# LPC43xx register map
File version: 10
CPU: CM4 r0p0, little endian, no MPU, no FPU, 3 interrupt priority bits
Registers are 32-bit, read-write, reset 0x0 unless marked. A register's access mark holds for its fields unless they carry their own. Offsets are from the block's base; [hi:lo] are bit positions; {n}, {i} and the like mark numbered series; 'fields as' and 'values as' point back to an identical list.

## GPDMA — General Purpose DMA (GPDMA)
Base 0x40002000
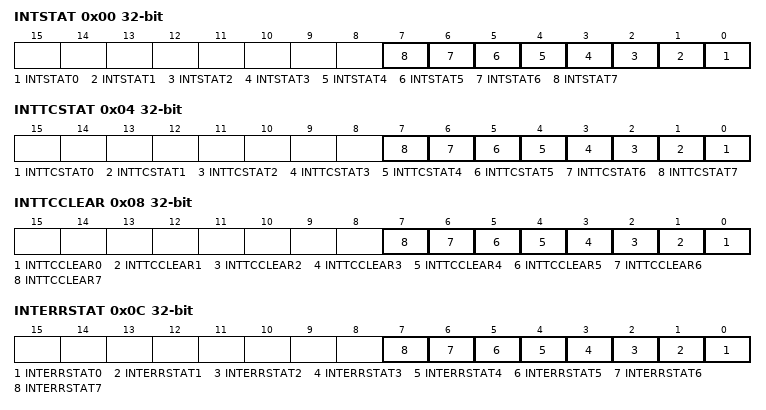
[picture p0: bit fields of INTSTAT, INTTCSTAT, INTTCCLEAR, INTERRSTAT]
0x00 INTSTAT ro — DMA Interrupt Status Register
  [n] INTSTAT{n} (n=0..7) — Status of DMA channel interrupts after masking. Each bit represents one channel: 0 - the corresponding channel has no active interrupt request. 1 - the corresponding channel does have an active interrupt request.
0x04 INTTCSTAT ro — DMA Interrupt Terminal Count Request Status Register
  [n] INTTCSTAT{n} (n=0..7) — Terminal count interrupt request status for DMA channels. Each bit represents one channel: 0 - the corresponding channel has no active terminal count interrupt request. 1 - the corresponding channel does have an active terminal count interrupt request.
0x08 INTTCCLEAR wo reset not defined — DMA Interrupt Terminal Count Request Clear Register
  [n] INTTCCLEAR{n} (n=0..7) — Allows clearing the Terminal count interrupt request (IntTCStat) for DMA channels. Each bit represents one channel: 0 - writing 0 has no effect. 1 - clears the corresponding channel terminal count interrupt.
0x0C INTERRSTAT ro — DMA Interrupt Error Status Register
  [n] INTERRSTAT{n} (n=0..7) — Interrupt error status for DMA channels. Each bit represents one channel: 0 - the corresponding channel has no active error interrupt request. 1 - the corresponding channel does have an active error interrupt request.
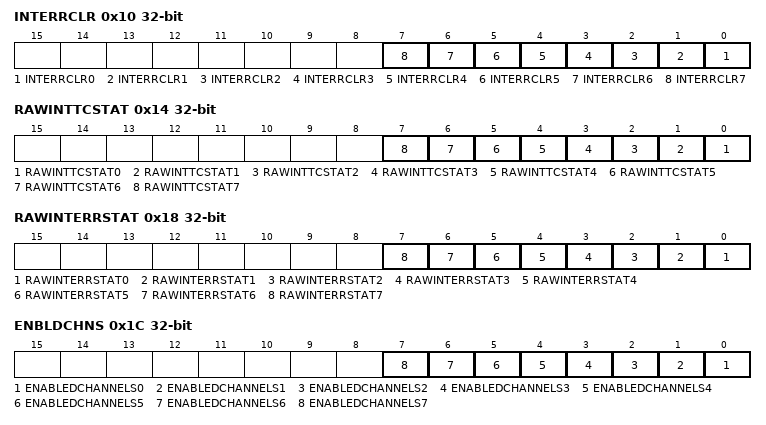
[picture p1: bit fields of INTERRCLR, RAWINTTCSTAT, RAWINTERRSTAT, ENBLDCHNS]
0x10 INTERRCLR wo reset not defined — DMA Interrupt Error Clear Register
  [n] INTERRCLR{n} (n=0..7) — Writing a 1 clears the error interrupt request (IntErrStat) for DMA channels. Each bit represents one channel: 0 - writing 0 has no effect. 1 - clears the corresponding channel error interrupt.
0x14 RAWINTTCSTAT ro — DMA Raw Interrupt Terminal Count Status Register
  [n] RAWINTTCSTAT{n} (n=0..7) — Status of the terminal count interrupt for DMA channels prior to masking. Each bit represents one channel: 0 - the corresponding channel has no active terminal count interrupt request. 1 - the corresponding channel does have an active terminal count interrupt request.
0x18 RAWINTERRSTAT ro — DMA Raw Error Interrupt Status Register
  [n] RAWINTERRSTAT{n} (n=0..7) — Status of the error interrupt for DMA channels prior to masking. Each bit represents one channel: 0 - the corresponding channel has no active error interrupt request. 1 - the corresponding channel does have an active error interrupt request.
0x1C ENBLDCHNS ro — DMA Enabled Channel Register
  [n] ENABLEDCHANNELS{n} (n=0..7) — Enable status for DMA channels. Each bit represents one channel: 0 - DMA channel is disabled. 1 - DMA channel is enabled.
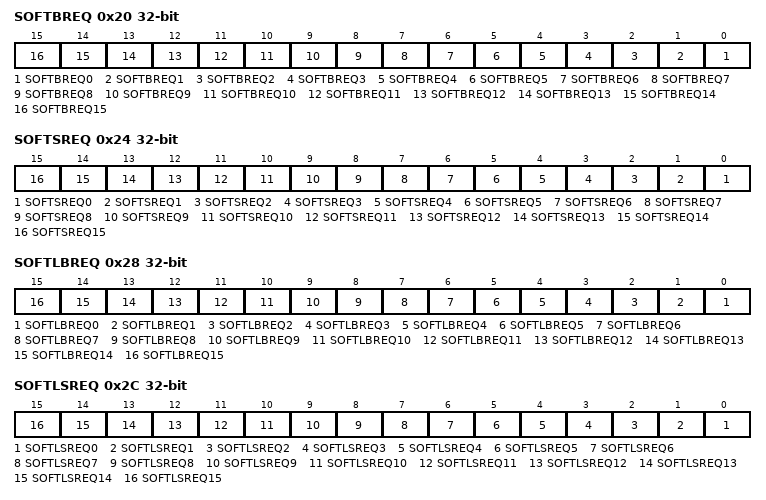
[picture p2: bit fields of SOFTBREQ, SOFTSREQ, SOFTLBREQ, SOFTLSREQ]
0x20 SOFTBREQ — DMA Software Burst Request Register
  [n] SOFTBREQ{n} (n=0..15) — Software burst request flags for each of 16 possible sources. Each bit represents one DMA request line or peripheral function (refer to Table 136 for peripheral hardware connections to the DMA controller): 0 - writing 0 has no effect. 1 - writing 1 generates a DMA burst request for the corresponding request line.
0x24 SOFTSREQ — DMA Software Single Request Register
  [n] SOFTSREQ{n} (n=0..15) — Software single transfer request flags for each of 16 possible sources. Each bit represents one DMA request line or peripheral function: 0 - writing 0 has no effect. 1 - writing 1 generates a DMA single transfer request for the corresponding request line.
0x28 SOFTLBREQ — DMA Software Last Burst Request Register
  [n] SOFTLBREQ{n} (n=0..15) — Software last burst request flags for each of 16 possible sources. Each bit represents one DMA request line or peripheral function: 0 - writing 0 has no effect. 1 - writing 1 generates a DMA last burst request for the corresponding request line.
0x2C SOFTLSREQ — DMA Software Last Single Request Register
  [n] SOFTLSREQ{n} (n=0..15) — Software last single transfer request flags for each of 16 possible sources. Each bit represents one DMA request line or peripheral function: 0 - writing 0 has no effect. 1 - writing 1 generates a DMA last single transfer request for the corresponding request line.
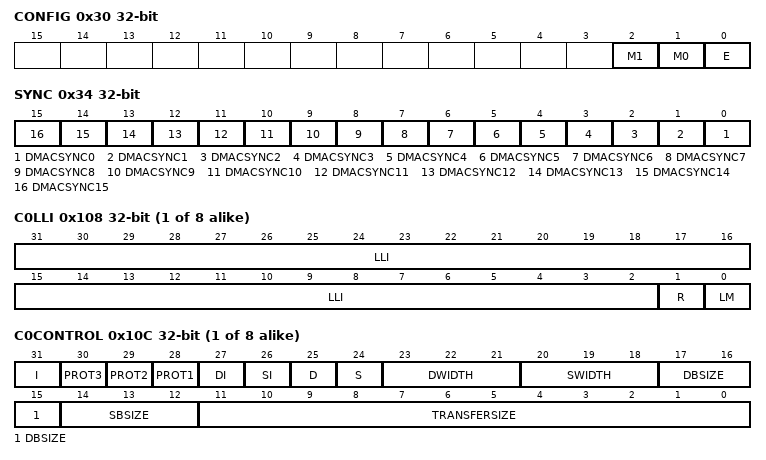
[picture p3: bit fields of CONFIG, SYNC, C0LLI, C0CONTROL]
0x30 CONFIG — DMA Configuration Register
  [2] M1 — AHB Master 1 endianness configuration:
    0=LITTLE_ENDIAN_MODE (Little-endian mode (default).); 1=BIG_ENDIAN_MODE_
  [1] M0 — AHB Master 0 endianness configuration:
    values as M1
  [0] E — DMA Controller enable:
    0=DISABLED__DEFAULT_ (Disabled (default). Disabling the DMA Controller reduces power consumption.); 1=ENABLED
0x34 SYNC — DMA Synchronization Register
  [n] DMACSYNC{n} (n=0..15) — Controls the synchronization logic for DMA request signals. Each bit represents one set of DMA request lines as described in the preceding text: 0 - synchronization logic for the corresponding DMA request signals are enabled. 1 - synchronization logic for the corresponding request line signals are disabled.
{0x100+0x20*i} C{i}SRCADDR (i=0..7) — DMA Channel Source Address Register
  [31:0] SRCADDR — DMA source address. Reading this register will return the current source address.
{0x104+0x20*i} C{i}DESTADDR (i=0..7) — DMA Channel Destination Address Register
  [31:0] DESTADDR — DMA Destination address. Reading this register will return the current destination address.
{0x108+0x20*i} C{i}LLI (i=0..7) — DMA Channel Linked List Item Register
  [31:2] LLI — Linked list item. Bits [31:2] of the address for the next LLI. Address bits [1:0] are 0.
  [1] R — Reserved, and must be written as 0, masked on read.
  [0] LM — AHB master select for loading the next LLI:
    0=AHB_MASTER_0_; 1=AHB_MASTER_1_
{0x10C+0x20*i} C{i}CONTROL (i=0..7) — DMA Channel Control Register
  [31] I — Terminal count interrupt enable bit.
    0=THE_TERMINAL_COUNT_INTERRUPT_IS_DISABLED; 1=THE_TERMINAL_COUNT_INTERRUPT_IS_ENABLED
  [30] PROT3 — Indicates that the access is cacheable or not cacheable:
    0=ACCESS_IS_NOT_CACHEA (Access is not cacheable.); 1=ACCESS_IS_CACHEABLE_
  [29] PROT2 — Indicates that the access is bufferable or not bufferable:
    0=ACCESS_IS_NOT_BUFFER (Access is not bufferable.); 1=ACCESS_IS_BUFFERABLE
  [28] PROT1 — Indicates that the access is in user mode or privileged mode:
    0=ACCESS_IS_IN_USER_MO (Access is in user mode); 1=ACCESS_IS_IN_PRIVILE (Access is in privileged mode.)
  [27] DI — Destination increment:
    0=THE_DESTINATION_ADDRESS_IS_NOT_INCREMENTED (The destination address is not incremented after each transfer.); 1=THE_DESTINATION_ADDRESS_IS_INCREMENTED (The destination address is incremented after each transfer.)
  [26] SI — Source increment:
    0=NOT_INCREMENT (The source address is not incremented after each transfer.); 1=INCREMENT (The source address is incremented after each transfer.)
  [25] D — Destination AHB master select: Only Master1 can access a peripheral. Master0 can only access memory.
    0=AHB_MASTER_0_SELECTE (AHB Master 0 selected for destination transfer.); 1=AHB_MASTER_1_SELECTE (AHB Master 1 selected for destination transfer.)
  [24] S — Source AHB master select:
    0=AHB_MASTER_0_SELECTE (AHB Master 0 selected for source transfer.); 1=AHB_MASTER_1_SELECTE (AHB Master 1 selected for source transfer.)
  [23:21] DWIDTH — Destination transfer width. Transfers wider than the AHB master bus width are not supported. The source and destination widths can be different from each other. The hardware automatically packs and unpacks the data as required. 0x3 to 0x7 - Reserved.
    0=BYTE_8_BIT; 1=HALFWORD_16_BIT; 2=WORD_32_BIT
  [20:18] SWIDTH — Source transfer width. Transfers wider than the AHB master bus width are illegal. The source and destination widths can be different from each other. The hardware automatically packs and unpacks the data as required. 0x3 to 0x7 - Reserved.
    0=BYTE_8_BIT; 1=HALFWORD_16_BIT; 2=WORD_32_BIT
  [17:15] DBSIZE — Destination burst size. Indicates the number of transfers that make up a destination burst transfer request. This value must be set to the burst size of the destination peripheral or, if the destination is memory, to the memory boundary size. The burst size is the amount of data that is transferred when the BREQ signal goes active in the destination peripheral.
    0=DESTINATION_BURST_1 (Destination burst size = 1); 1=DESTINATION_BURST_4 (Destination burst size = 4); 2=DESTINATION_BURST_8 (Destination burst size = 8); 3=DESTINATION_BURST_16 (Destination burst size = 16); 4=DESTINATION_BURST_32 (Destination burst size = 32); 5=DESTINATION_BURST_64 (Destination burst size = 64); 6=DESTINATION_BURST_128 (Destination burst size = 128); 7=DESTINATION_BURST_256 (Destination burst size = 256)
  [14:12] SBSIZE — Source burst size. Indicates the number of transfers that make up a source burst. This value must be set to the burst size of the source peripheral, or if the source is memory, to the memory boundary size (see Figure 3). The burst size is the amount of data that is transferred when the BREQ signal goes active in the source peripheral.
    0=SOURCE_BURST_1 (Source burst size = 1); 1=SOURCE_BURST_4 (Source burst size = 4); 2=SOURCE_BURST_8 (Source burst size = 8); 3=SOURCE_BURST_16 (Source burst size = 16); 4=SOURCE_BURST_32 (Source burst size = 32); 5=SOURCE_BURST_64 (Source burst size = 64); 6=SOURCE_BURST_128 (Source burst size = 128); 7=SOURCE_BURST_256 (Source burst size = 256)
  [11:0] TRANSFERSIZE — Transfer size in byte. A write to this field sets the size of the transfer when the DMA Controller is the flow controller. The transfer size value must be set before the channel is enabled. Transfer size is updated as data transfers are completed. A read from this field indicates the number of transfers completed on the destination bus. Reading the register when the channel is active does not give useful information because by the time that the software has processed the value read, the channel might have progressed. It is intended to be used only when a channel is enabled and then disabled. The transfer size value is not used if the DMA Controller is not the flow controller.
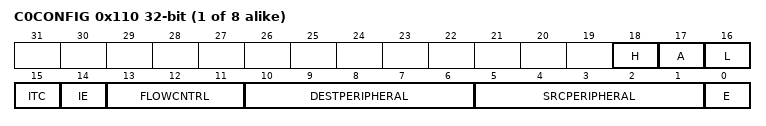
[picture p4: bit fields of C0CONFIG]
{0x110+0x20*i} C{i}CONFIG (i=0..7) — DMA Channel Configuration Register
  [18] H — Halt: 0 = enable DMA requests. 1 = ignore further source DMA requests. The contents of the channel FIFO are drained. This value can be used with the Active and Channel Enable bits to cleanly disable a DMA channel.
    0=ENABLE_DMA_REQUESTS_; 1=IGNORE_FURTHER_SOURC (Ignore further source DMA requests.)
  [17] A — Active: 0 = there is no data in the FIFO of the channel. 1 = the channel FIFO has data. This value can be used with the Halt and Channel Enable bits to cleanly disable a DMA channel. This is a read-only bit.
  [16] L — Lock. When set, this bit enables locked transfers.
  [15] ITC — Terminal count interrupt mask. When cleared, this bit masks out the terminal count interrupt of the relevant channel.
  [14] IE — Interrupt error mask. When cleared, this bit masks out the error interrupt of the relevant channel.
  [13:11] FLOWCNTRL — Flow control and transfer type. This value indicates the flow controller and transfer type. The flow controller can be the DMA Controller, the source peripheral, or the destination peripheral. The transfer type can be memory-to-memory, memory-to-peripheral, peripheral-to-memory, or peripheral-to-peripheral. Refer to Table 157 for the encoding of this field.
    0=MEMORY_TO_MEMORY (Memory to memory (DMA control)); 1=MEMORY_TO_PERIPHERAL_DMA_CONTROL; 2=PERIPHERAL_TO_MEMORY_DMA_CONTROL; 3=SOURCE_PERIPHERAL_TO_DMA_CONTROL (Source peripheral to destination peripheral (DMA control)); 4=SOURCE_PERIPHERAL_TO_DEST_CONTROL (Source peripheral to destination peripheral (destination control)); 5=MEMORY_TO_PERIPHERAL_PERIPHERAL_CONTROL; 6=PERIPHERAL_TO_MEMORY_PERIPHERAL_CONTROL; 7=SOURCE_PERIPHERAL_TO_SOURCE_CONTROL (Source peripheral to destination peripheral (source control))
  [10:6] DESTPERIPHERAL — Destination peripheral. This value selects the DMA destination request peripheral. This field is ignored if the destination of the transfer is to memory. See Table 136 for details.
    0=DESTINATION_EQ_SPIFI (Destination = SPIFI); 1=DESTINATION_EQ_TIMER_0_MATCH_0_UART0_TRANSMIT (Destination = Timer 0 match 0/UART0 transmit); 2=DESTINATION_EQ_TIMER_0_MATCH_1_UART0_RECEIEVE (Destination = Timer 0 match 1/UART0 receive); 3=DESTINATION_EQ_TIMER_1_MATCH_0_UART1_TRANSMIT (Destination = Timer 1 match 0/UART1 transmit); 4=DESTINATION_EQ_TIMER_1_MATCH_1_UART1_RECEIVE (Destination = Timer 1 match 1/UART 1 receive); 5=DESTINATION_EQ_TIMER_2_MATCH_0_UART2_TRANSMIT (Destination = Timer 2 match 0/UART 2 transmit); 6=DESTINATION_EQ_TIMER_2_MATCH_1_UART2_RECEIVE (Destination = Timer 2 match 1/UART 2 receive); 7=DESTINATION_EQ_TIMER_3_MATCH_0_UART3_TRANSMIT_DMA_REQ_0 (Destination = Timer 3 match 0/UART3 transmit/SCT DMA request 0); 8=DESTINATION_EQ_TIMER_3_MATCH_1_UART3_RECEIVE_DMA_REQ_1 (Destination = Timer 3 match 1/UART3 receive/SCT DMA request 1); 9=DESTINATION_EQ_SSP0_RECEIVE_CH0 (Destination = SSP0 receive/I2S channel 0); 10=DESTINATION_EQ_SSP0_TRANSMIT_CH1 (Destination = SSP0 transmit/I2S channel 1); 11=DESTINATION_EQ_SSP1_RECEIVE (Destination = SSP1 receive); 12=DESTINATION_EQ_SSP1_TRANSMIT (Destination = SSP1 transmit); 13=DESTINATION_EQ_ADC0 (Destination = ADC0); 14=DESTINATION_EQ_ADC1 (Destination = ADC1); 15=DESTINATION_EQ_DAC (Destination = DAC)
  [5:1] SRCPERIPHERAL — Source peripheral. This value selects the DMA source request peripheral. This field is ignored if the source of the transfer is from memory. See Table 136 for details.
    0=SOURCE_EQ_SPIFI (Source = SPIFI); 1=SOURCE_EQ_TIMER_0_MATCH_0_UART0_TRANSMIT (Source = Timer 0 match 0/UART0 transmit); 2=SOURCE_EQ_TIMER_0_MATCH_1_UART0_RECEIVE (Source = Timer 0 match 1/UART0 receive); 3=SOURCE_EQ_TIMER_1_MATCH_0_UART1_TRANSMIT (Source = Timer 1 match 0/UART1 transmit); 4=SOURCE_EQ_TIMER_1_MATCH_1_UART1_RECEIVE (Source = Timer 1 match 1/UART 1 receive); 5=SOURCE_EQ_TIMER_2_MATCH_0_UART2_TRANSMIT (Source = Timer 2 match 0/UART 2 transmit); 6=SOURCE_EQ_TIMER_2_MATCH_1_UART2_RECEIVE (Source = Timer 2 match 1/UART 2 receive); 7=SOURCE_EQ_TIMER_3_MATCH_0_UART3_RECEIVE_DMA_REQ_0 (Source = Timer 3 match 0/UART3 transmit/SCT DMA request 0); 8=SOURCE_EQ_TIMER_3_MATCH_1_UART3_RECEIVE_DMA_REQ_1 (Source = Timer 3 match 1/UART3 receive/SCT DMA request 1); 9=SOURCE_EQ_SSP0_RECEIVE_CH0 (Source = SSP0 receive/I2S channel 0); 10=SOURCE_EQ_SSP0_TRANSMIT_CH1 (Source = SSP0 transmit/I2S channel 1); 11=SOURCE_EQ_SSP1_RECEIVE (Source = SSP1 receive); 12=SOURCE_EQ_SSP1_TRANSMIT (Source = SSP1 transmit); 13=SOURCE_EQ_ADC0 (Source = ADC0); 14=SOURCE_EQ_ADC1 (Source = ADC1); 15=SOURCE_EQ_DAC (Source = DAC)
  [0] E — Channel enable. Reading this bit indicates whether a channel is currently enabled or disabled: The Channel Enable bit status can also be found by reading the EnbldChns Register. A channel can be disabled by clearing the Enable bit. This causes the current AHB transfer (if one is in progress) to complete and the channel is then disabled. Any data in the FIFO of the relevant channel is lost. Restarting the channel by setting the Channel Enable bit has unpredictable effects, the channel must be fully re-initialized. The channel is also disabled, and Channel Enable bit cleared, when the last LLI is reached, the DMA transfer is completed, or if a channel error is encountered. If a channel must be disabled without losing data in the FIFO, the Halt bit must be set so that further DMA requests are ignored. The Active bit must then be polled until it reaches 0, indicating that there is no data left in the FIFO. Finally, the Channel Enable bit can be cleared.
    0=CHANNEL_DISABLED_; 1=CHANNEL_ENABLED_
